# N32H7xx register map
Vendor: Nationstech Ltd.; File version: 1.0
Registers are 32-bit, read-write, reset 0x0 unless marked. A register's access mark holds for its fields unless they carry their own. Offsets are from the block's base; [hi:lo] are bit positions; {n}, {i} and the like mark numbered series.

## USB_HS1_WRP — USB high speed Wrapper control
Base 0x40140000
Same registers: USB_HS2_WRP 0x400A0000
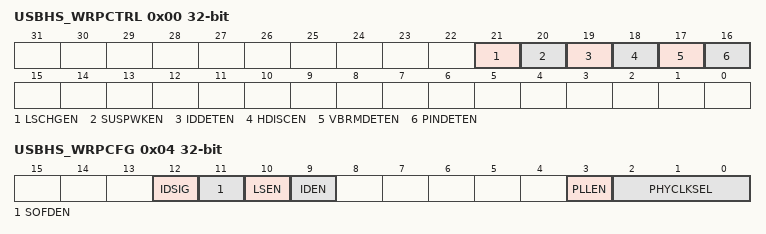
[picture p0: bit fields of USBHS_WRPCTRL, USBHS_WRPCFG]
0x00 USBHS_WRPCTRL
  [21] LSCHGEN, [20] SUSPWKEN, [19] IDDETEN, [18] HDISCEN, [17] VBRMDETEN, [16] PINDETEN
0x04 USBHS_WRPCFG
  [12] IDSIG, [11] SOFDEN, [10] LSEN, [9] IDEN, [3] PLLEN, [2:0] PHYCLKSEL

## CRC — Cyclic Redundancy Check
Base 0x58032000
0x00 CRC_DAT reset 0xFFFFFFFF — CRC Data Register
  [31:0] DAT — This register is used to write new data to the CRC calculator
0x04 CRC_IDAT — CRC Independent Data Register
  [31:0] IDAT — General-purpose 32-bit data register
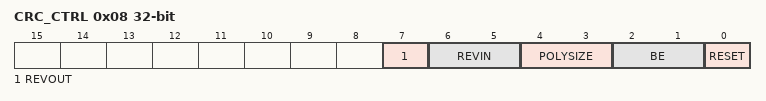
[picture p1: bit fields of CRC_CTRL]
0x08 CRC_CTRL — CRC Control Register
  [7] REVOUT — Reverse output data
  [6:5] REVIN — Reverse input data
  [4:3] POLYSIZE — Polynomial size
  [2:1] BE — CRC byte Endian
  [0] RESET — RESET bit
0x0C CRC_LRC — LRC Value Register
  [31:0] LRC — LRC Value
0x10 CRC_INIT reset 0xFFFFFFFF — CRC Initial Value Register
  [31:0] INIT — Programmable initial CRC value
0x14 CRC_POL reset 0x4C11DB7 — CRC Polynomial Register
  [31:0] POL — Programmable polynomial
0x18 CRC_INXORDAT — CRC Input XOR data Register
  [31:0] INXOR — This register is used to set CRC_DAT XOR calculation value before CRC calculation
0x1C CRC_OUTXORDAT — CRC Output XOR data Register
  [31:0] OUTXOR — This register is used to set CRC_DAT XOR calculation value after CRC calculation

## OTPC — One Time Programble Controller
Base 0x51118000
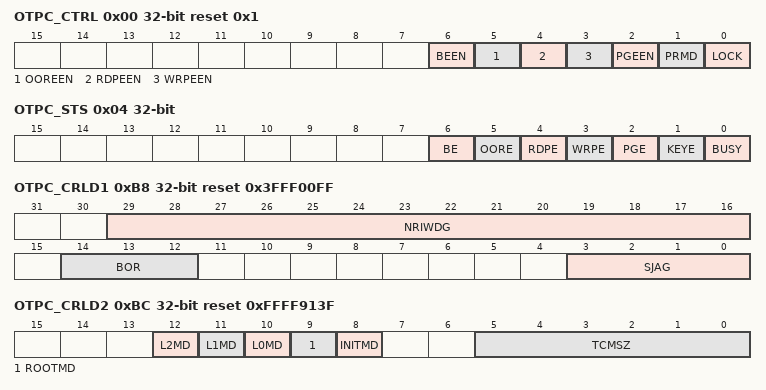
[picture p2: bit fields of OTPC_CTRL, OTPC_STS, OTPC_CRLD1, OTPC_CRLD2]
0x00 OTPC_CTRL reset 0x1 — OTPC Control Register
  [6] BEEN, [5] OOREEN, [4] RDPEEN, [3] WRPEEN, [2] PGEEN, [1] PRMD, [0] LOCK
0x04 OTPC_STS — OTPC Status Register
  [6] BE, [5] OORE, [4] RDPE, [3] WRPE, [2] PGE, [1] KEYE, [0] BUSY
0x08 OTPC_KEY — OTPC Key Regsiter
0x0C OTPC_USC reset 0x12F — OTPC Us Counter Register
  [8:0] VAL
0x10 OTPC_ADDR — OTPC Address Register
0x14 OTPC_RDATA — OTPC Read Data Register
  [31:0] DAT
0x18 OTPC_WDATA — OTPC Write Data Regsiter
  [31:0] DAT
0x20 OTPC_SECJVLD reset 0xFFFF — nan
  [15:0] USR_NVR_VLD
0x28 OTPC_SECMDVLD reset 0xFFFF — nan
  [15:0] USR_NVR_VLD
0x30 OTPC_RDP2PVLD reset 0x1FFFF — nan
  [15:0] USR_NVR_VLD
0x38 OTPC_BTMVLD reset 0xFFFF — nan
  [15:0] USR_NVR_VLD
0x3C OTPC_BORVLD reset 0xFFFF — nan
  [15:0] USR_NVR_VLD
0x40 OTPC_IWDGVLD reset 0xFFFF — nan
  [15:0] USR_NVR_VLD
0x44 OTPC_TCMSZVLD reset 0xFFFF — nan
  [15:0] USR_NVR_VLD
0x50 OTPC_JTAGKVLD reset 0x1FFFF — nan
  [15:0] USR_NVR_VLD
{0x50+4i} OTPC_REKU{i}VLD reset 0xFFFF (i=1..3) — nan
  [15:0] USR_NVR_VLD
0x60 OTPC_REKU4V reset 0xFFFF — nan
  [15:0] USR_NVR_VLD
{0x60+4i} OTPC_IDKU{i}VLD reset 0xFFFF (i=1..4) — nan
  [15:0] USR_NVR_VLD
{0x74+4i} OTPC_UMUU{i} reset 0xFFFFFFFF (i=0..7) — OTPC USRMEM Unused {i}
  [31:0] UU
0xB8 OTPC_CRLD1 reset 0x3FFF00FF — nan
  [29:16] NRIWDG, [14:12] BOR, [3:0] SJAG
0xBC OTPC_CRLD2 reset 0xFFFF913F — nan
  [12] L2MD, [11] L1MD, [10] L0MD, [9] ROOTMD, [8] INITMD, [5:0] TCMSZ

## ECCMON1P1 — ECC Monitoring
Base 0x51104000
Same registers: ECCMON2 0x400F0000, ECCMON1P2 0x51104400, ECCMON1P3 0x51104800, ECCMON1P4 0x51104C00, ECCMON3 0x58036000
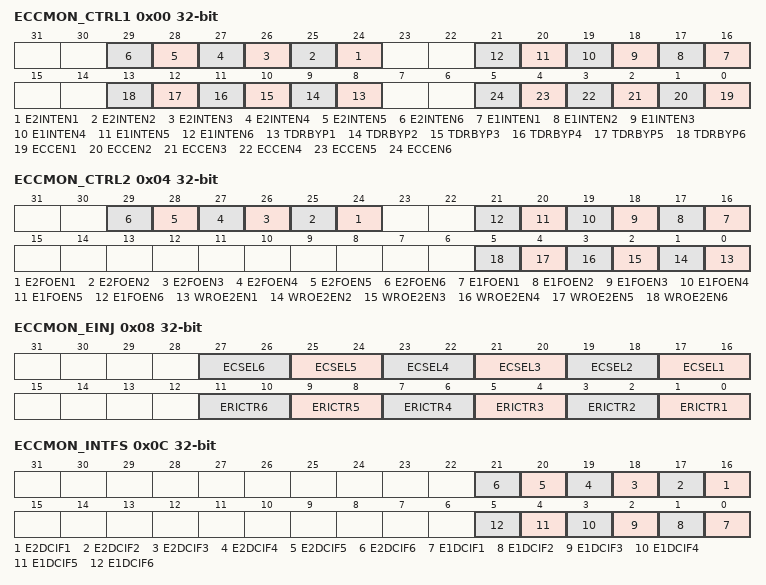
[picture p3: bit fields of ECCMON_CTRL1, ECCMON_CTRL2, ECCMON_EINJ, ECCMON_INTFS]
0x00 ECCMON_CTRL1 — Control Register 1
  [n+23] E2INTEN{n} (n=1..6), [n+15] E1INTEN{n} (n=1..6), [n+7] TDRBYP{n} (n=1..6), [n-1] ECCEN{n} (n=1..6)
0x04 ECCMON_CTRL2 — Control Register 2
  [n+23] E2FOEN{n} (n=1..6), [n+15] E1FOEN{n} (n=1..6), [n-1] WROE2EN{n} (n=1..6)
0x08 ECCMON_EINJ — Error Injection Register
  [2n+15:2n+14] ECSEL{n} (n=1..6), [2n-1:2n-2] ERICTR{n} (n=1..6)
0x0C ECCMON_INTFS — Interrupt Flag Shadow Register
  [n+15] E2DCIF{n} (n=1..6), [n-1] E1DCIF{n} (n=1..6)
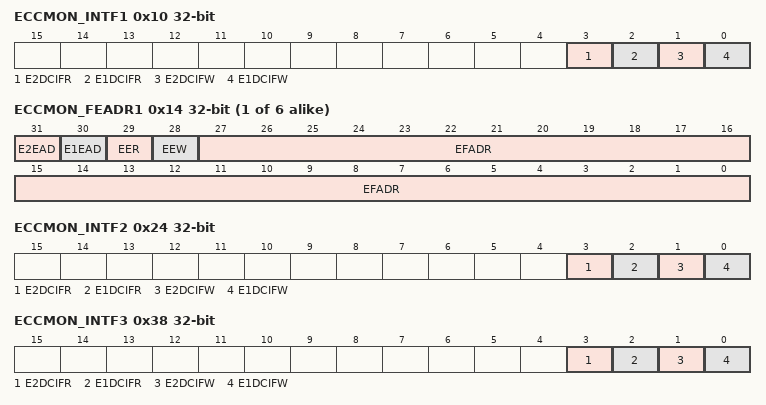
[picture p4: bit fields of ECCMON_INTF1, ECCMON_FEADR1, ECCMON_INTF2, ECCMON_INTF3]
0x10 ECCMON_INTF1 — Mermory 1 Interrupt Flag Register
  [3] E2DCIFR, [2] E1DCIFR, [1] E2DCIFW, [0] E1DCIFW
{0x0+0x14*i} ECCMON_FEADR{i} (i=1..6) — Mermory {i} ECC Fail Event Address Register
  [31] E2EAD, [30] E1EAD, [29] EER, [28] EEW, [27:0] EFADR
0x18 ECCMON_FEDATL1 — Mermory 1 ECC Fail Event Data Register 0
  [31:0] ERDATL
{0x8+0x14*i} ECCMON_FEDATH{i} (i=1..6) — Mermory {i} ECC Fail Event Data Register 1
  [31:0] ERDATH
{0xC+0x14*i} ECCMON_FECOD{i} (i=1..6) — Mermory {i} ECC Fail Event ECC Code Register
  [6:0] ERCOD
0x24 ECCMON_INTF2 — Mermory 2 Interrupt Flag Register
  [3] E2DCIFR, [2] E1DCIFR, [1] E2DCIFW, [0] E1DCIFW
0x2C ECCMON_FEDATL2 — SRAM1 ECC Fail Event Data Register 0
  [31:0] ERDATL
0x38 ECCMON_INTF3 — Mermory 3 Interrupt Flag Register
  [3] E2DCIFR, [2] E1DCIFR, [1] E2DCIFW, [0] E1DCIFW
{0x4+0x14*i} ECCMON_FEDATL{i} (i=3..6) — Mermory {i} ECC Fail Event Data Register 0
  [31:0] ERDATL
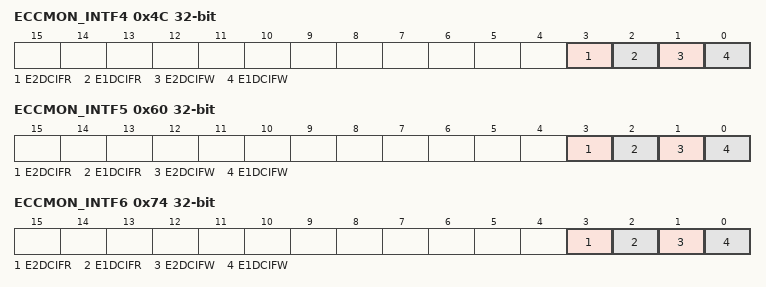
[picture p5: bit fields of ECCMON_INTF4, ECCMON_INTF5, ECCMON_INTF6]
0x4C ECCMON_INTF4 — Mermory 4 Interrupt Flag Register
  [3] E2DCIFR, [2] E1DCIFR, [1] E2DCIFW, [0] E1DCIFW
0x60 ECCMON_INTF5 — Mermory 5 Interrupt Flag Register
  [3] E2DCIFR, [2] E1DCIFR, [1] E2DCIFW, [0] E1DCIFW
0x74 ECCMON_INTF6 — Mermory 6 Interrupt Flag Register
  [3] E2DCIFR, [2] E1DCIFR, [1] E2DCIFW, [0] E1DCIFW
